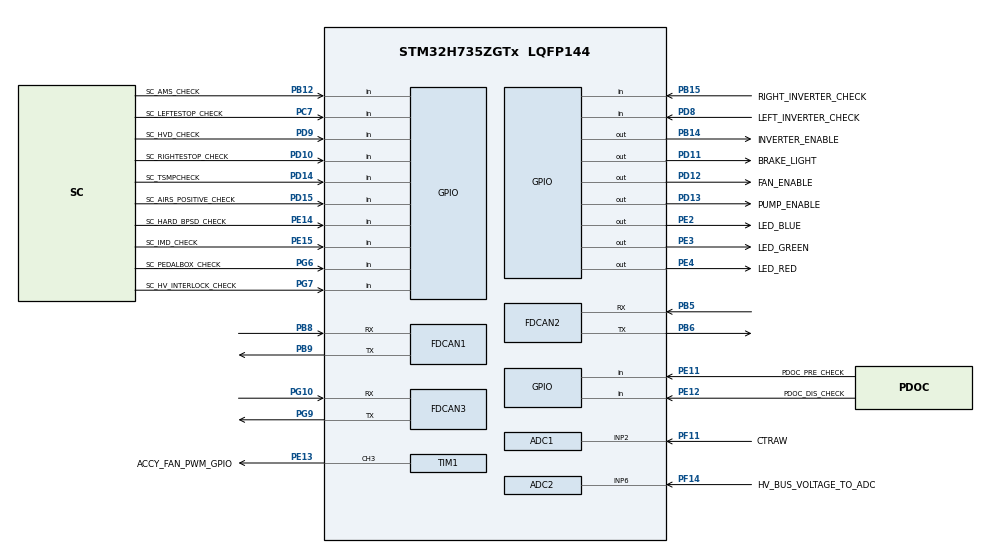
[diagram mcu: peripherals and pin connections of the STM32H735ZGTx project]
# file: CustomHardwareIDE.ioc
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ADC1.Channel-0\#ChannelRegularConversion=ADC_CHANNEL_2
ADC1.ClockPrescaler=ADC_CLOCK_ASYNC_DIV6
ADC1.NbrOfConversionFlag=1
ADC1.OffsetNumber-0\#ChannelRegularConversion=ADC_OFFSET_NONE
ADC1.OffsetSignedSaturation-0\#ChannelRegularConversion=DISABLE
ADC1.Rank-0\#ChannelRegularConversion=1
ADC1.SamplingTime-0\#ChannelRegularConversion=ADC_SAMPLETIME_1CYCLE_5
ADC1.master=1
ADC2.Channel-0\#ChannelRegularConversion=ADC_CHANNEL_6
ADC2.ClockPrescaler=ADC_CLOCK_ASYNC_DIV6
ADC2.NbrOfConversionFlag=1
ADC2.OffsetNumber-0\#ChannelRegularConversion=ADC_OFFSET_NONE
ADC2.OffsetSignedSaturation-0\#ChannelRegularConversion=DISABLE
ADC2.Rank-0\#ChannelRegularConversion=1
ADC2.SamplingTime-0\#ChannelRegularConversion=ADC_SAMPLETIME_1CYCLE_5
FDCAN1.CalculateBaudRateNominal=1062500
FDCAN1.CalculateTimeBitNominal=941
FDCAN1.CalculateTimeQuantumNominal=29.41176470588235
FDCAN1.DataPrescaler=1
FDCAN1.DataSyncJumpWidth=4
FDCAN1.DataTimeSeg1=27
FDCAN1.DataTimeSeg2=4
FDCAN1.NominalPrescaler=1
FDCAN1.NominalSyncJumpWidth=4
FDCAN1.NominalTimeSeg1=27
FDCAN1.NominalTimeSeg2=4
FDCAN1.RxFifo0ElmtSize=FDCAN_DATA_BYTES_12
FDCAN1.RxFifo0ElmtsNbr=1
FDCAN1.TxElmtSize=FDCAN_DATA_BYTES_12
FDCAN1.TxFifoQueueElmtsNbr=1
FDCAN2.CalculateBaudRateNominal=708333
FDCAN2.CalculateTimeBitNominal=1411
FDCAN2.CalculateTimeQuantumNominal=470.5882352941176
FDCAN3.CalculateBaudRateNominal=708333
FDCAN3.CalculateTimeBitNominal=1411
FDCAN3.CalculateTimeQuantumNominal=470.5882352941176
FREERTOS.Tasks01=defaultTask,24,128,StartDefaultTask,Default,NULL,Dynamic,NULL,NULL
FREERTOS.configTIMER_TASK_PRIORITY=45
FREERTOS.configUSE_NEWLIB_REENTRANT=1
Mcu.Family=STM32H7
Mcu.Name=STM32H735ZGTx
Mcu.Package=LQFP144
NVIC.FDCAN1_IT0_IRQn=true\:5\:0\:false\:false\:true\:true\:true\:true\:true
NVIC.PriorityGroup=NVIC_PRIORITYGROUP_4
NVIC.TIM2_IRQn=true\:15\:0\:false\:false\:true\:false\:false\:true\:true
NVIC.TimeBase=TIM2_IRQn
NVIC.TimeBaseIP=TIM2
PA13(JTMS/SWDIO).Mode=JTAG_5_pins
PA13(JTMS/SWDIO).Signal=DEBUG_JTMS-SWDIO
PA14(JTCK/SWCLK).Mode=JTAG_5_pins
PA14(JTCK/SWCLK).Signal=DEBUG_JTCK-SWCLK
PA15(JTDI).Mode=JTAG_5_pins
PA15(JTDI).Signal=DEBUG_JTDI
PB12.GPIO_Label=SC_AMS_CHECK
PB12.Signal=GPIO_Input
PB14.GPIO_Label=INVERTER_ENABLE
PB14.Signal=GPIO_Output
PB15.GPIO_Label=RIGHT_INVERTER_CHECK
PB15.Signal=GPIO_Input
PB3(JTDO/TRACESWO).Mode=JTAG_5_pins
PB3(JTDO/TRACESWO).Signal=DEBUG_JTDO-SWO
PB4(NJTRST).Mode=JTAG_5_pins
PB4(NJTRST).Signal=DEBUG_JTRST
PB5.Mode=FDCAN_Activate
PB5.Signal=FDCAN2_RX
PB6.Mode=FDCAN_Activate
PB6.Signal=FDCAN2_TX
PB8.Mode=FDCAN_Activate
PB8.Signal=FDCAN1_RX
PB9.Mode=FDCAN_Activate
PB9.Signal=FDCAN1_TX
PC7.GPIO_Label=SC_LEFTESTOP_CHECK
PC7.Signal=GPIO_Input
PD10.GPIO_Label=SC_RIGHTESTOP_CHECK
PD10.Signal=GPIO_Input
PD11.GPIO_Label=BRAKE_LIGHT
PD11.Signal=GPIO_Output
PD12.GPIO_Label=FAN_ENABLE
PD12.Signal=GPIO_Output
PD13.GPIO_Label=PUMP_ENABLE
PD13.Signal=GPIO_Output
PD14.GPIO_Label=SC_TSMPCHECK
PD14.Signal=GPIO_Input
PD15.GPIO_Label=SC_AIRS_POSITIVE_CHECK
PD15.Signal=GPIO_Input
PD8.GPIO_Label=LEFT_INVERTER_CHECK
PD8.Signal=GPIO_Input
PD9.GPIO_Label=SC_HVD_CHECK
PD9.Signal=GPIO_Input
PE11.GPIO_Label=PDOC_PRE_CHECK
PE11.Signal=GPIO_Input
PE12.GPIO_Label=PDOC_DIS_CHECK
PE12.Signal=GPIO_Input
PE13.GPIO_Label=ACCY_FAN_PWM_GPIO
PE13.Signal=S_TIM1_CH3
PE14.GPIO_Label=SC_HARD_BPSD_CHECK
PE14.Signal=GPIO_Input
PE15.GPIO_Label=SC_IMD_CHECK
PE15.Signal=GPIO_Input
PE2.GPIO_Label=LED_BLUE
PE2.Signal=GPIO_Output
PE3.GPIO_Label=LED_GREEN
PE3.Signal=GPIO_Output
PE4.GPIO_Label=LED_RED
PE4.GPIO_PuPd=GPIO_NOPULL
PE4.Signal=GPIO_Output
PF11.GPIO_Label=CTRAW
PF11.Mode=IN2-Single-Ended
PF11.Signal=ADC1_INP2
PF14.GPIO_Label=HV_BUS_VOLTAGE_TO_ADC
PF14.Mode=IN6-Single-Ended
PF14.Signal=ADC2_INP6
PG10.Mode=FDCAN_Activate
PG10.Signal=FDCAN3_RX
PG6.GPIO_Label=SC_PEDALBOX_CHECK
PG6.Signal=GPIO_Input
PG7.GPIO_Label=SC_HV_INTERLOCK_CHECK
PG7.Signal=GPIO_Input
PG9.Mode=FDCAN_Activate
PG9.Signal=FDCAN3_TX
PH0-OSC_IN.Mode=HSE-External-Oscillator
PH0-OSC_IN.Signal=RCC_OSC_IN
PH1-OSC_OUT.Mode=HSE-External-Oscillator
PH1-OSC_OUT.Signal=RCC_OSC_OUT
ProjectManager.HeapSize=0x200
ProjectManager.StackSize=0x400
ProjectManager.TargetToolchain=STM32CubeIDE
RCC.ADCCLockSelection=RCC_ADCCLKSOURCE_CLKP
RCC.ADCFreq_Value=64000000
RCC.APB1Freq_Value=136000000
RCC.APB2Freq_Value=136000000
RCC.APB3Freq_Value=136000000
RCC.APB4Freq_Value=136000000
RCC.CortexFreq_Value=544000000
RCC.D1PPRE=RCC_APB3_DIV2
RCC.D2PPRE1=RCC_APB1_DIV2
RCC.D2PPRE2=RCC_APB2_DIV2
RCC.D3PPRE=RCC_APB4_DIV2
RCC.DIVM1=8
RCC.DIVM2=1
RCC.DIVN1=68
RCC.DIVN2=384
RCC.DIVP1=1
RCC.DIVP2=4
RCC.DIVQ1=16
RCC.HCLKFreq_Value=272000000
RCC.HPRE=RCC_HCLK_DIV2
RCC.HSE_VALUE=16000000
RCC.SYSCLKFreq_VALUE=544000000
RCC.SYSCLKSource=RCC_SYSCLKSOURCE_PLLCLK
RCC.SupplySource=PWR_LDO_SUPPLY
RCC.USBFreq_Value=34000000
SH.S_TIM1_CH3.0=TIM1_CH3,PWM Generation3 CH3
TIM1.Channel-PWM\ Generation3\ CH3=TIM_CHANNEL_3
VP_FREERTOS_VS_CMSIS_V2.Mode=CMSIS_V2
VP_MEMORYMAP_VS_MEMORYMAP.Mode=CurAppReg
VP_SYS_VS_tim2.Mode=TIM2
VP_TIM1_VS_ClockSourceITR.Mode=TriggerSource_ITR0
VP_TIM1_VS_ControllerModeClock.Mode=Clock Mode
board=custom

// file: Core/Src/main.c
/* USER CODE BEGIN Header */
/**
  ******************************************************************************
  * @file           : main.c
  * @brief          : Main program body
  ******************************************************************************
  * @attention
  *
  * Copyright (c) 2025 STMicroelectronics.
  * All rights reserved.
  *
  * This software is licensed under terms that can be found in the LICENSE file
  * in the root directory of this software component.
  * If no LICENSE file comes with this software, it is provided AS-IS.
  *
  ******************************************************************************
  */
/* USER CODE END Header */
#include "main.h"
#include "cmsis_os.h"

FDCAN_HandleTypeDef hfdcan1;
FDCAN_HandleTypeDef hfdcan2;
FDCAN_HandleTypeDef hfdcan3;

/* Definitions for defaultTask */
osThreadId_t defaultTaskHandle;
const osThreadAttr_t defaultTask_attributes = {
  .name = "defaultTask",
  .stack_size = 128 * 4,
  .priority = (osPriority_t) osPriorityNormal,
};

void SystemClock_Config(void);
void PeriphCommonClock_Config(void);
static void MX_FDCAN1_Init(void);
static void MX_FDCAN2_Init(void);
static void MX_FDCAN3_Init(void);
static void MX_ADC1_Init(void);
static void MX_ADC2_Init(void);
static void MX_TIM1_Init(void);
void StartDefaultTask(void *argument);

int main(void)
{

  /* MCU Configuration--------------------------------------------------------*/

  /* Reset of all peripherals, Initializes the Flash interface and the Systick. */
  HAL_Init();

  /* Configure the system clock */
  SystemClock_Config();

  /* Configure the peripherals common clocks */
  PeriphCommonClock_Config();

  /* Initialize all configured peripherals */
  MX_GPIO_Init();
  MX_FDCAN1_Init();
  MX_FDCAN2_Init();
  MX_FDCAN3_Init();
  MX_ADC1_Init();
  MX_ADC2_Init();
  MX_TIM1_Init();

  /* Init scheduler */
  osKernelInitialize();

  /* Create the thread(s) */
  /* creation of defaultTask */
  defaultTaskHandle = osThreadNew(StartDefaultTask, NULL, &defaultTask_attributes);

  /* Start scheduler */
  osKernelStart();

  /* We should never get here as control is now taken by the scheduler */

  /* Infinite loop */
  while (1)
  {

  }
}

void SystemClock_Config(void)
{
  LL_FLASH_SetLatency(LL_FLASH_LATENCY_3);
  while(LL_FLASH_GetLatency()!= LL_FLASH_LATENCY_3)
  {
  }
  LL_PWR_ConfigSupply(LL_PWR_LDO_SUPPLY);
  LL_PWR_SetRegulVoltageScaling(LL_PWR_REGU_VOLTAGE_SCALE0);
  while (LL_PWR_IsActiveFlag_VOS() == 0)
  {
  }
  LL_RCC_HSI_Enable();

   /* Wait till HSI is ready */
  while(LL_RCC_HSI_IsReady() != 1)
  {

  }
  LL_RCC_HSI_SetCalibTrimming(64);
  LL_RCC_HSI_SetDivider(LL_RCC_HSI_DIV1);
  LL_RCC_PLL_SetSource(LL_RCC_PLLSOURCE_HSI);
  LL_RCC_PLL1P_Enable();
  LL_RCC_PLL1Q_Enable();
  LL_RCC_PLL1R_Enable();
  LL_RCC_PLL1_SetVCOInputRange(LL_RCC_PLLINPUTRANGE_8_16);
  LL_RCC_PLL1_SetVCOOutputRange(LL_RCC_PLLVCORANGE_WIDE);
  LL_RCC_PLL1_SetM(8);
  LL_RCC_PLL1_SetN(68);
  LL_RCC_PLL1_SetP(1);
  LL_RCC_PLL1_SetQ(16);
  LL_RCC_PLL1_SetR(2);
  LL_RCC_PLL1_Enable();

   /* Wait till PLL is ready */
  while(LL_RCC_PLL1_IsReady() != 1)
  {
  }

   /* Intermediate AHB prescaler 2 when target frequency clock is higher than 80 MHz */
   LL_RCC_SetAHBPrescaler(LL_RCC_AHB_DIV_2);

  LL_RCC_SetSysClkSource(LL_RCC_SYS_CLKSOURCE_PLL1);

   /* Wait till System clock is ready */
  while(LL_RCC_GetSysClkSource() != LL_RCC_SYS_CLKSOURCE_STATUS_PLL1)
  {

  }
  LL_RCC_SetSysPrescaler(LL_RCC_SYSCLK_DIV_1);
  LL_RCC_SetAHBPrescaler(LL_RCC_AHB_DIV_2);
  LL_RCC_SetAPB1Prescaler(LL_RCC_APB1_DIV_2);
  LL_RCC_SetAPB2Prescaler(LL_RCC_APB2_DIV_2);
  LL_RCC_SetAPB3Prescaler(LL_RCC_APB3_DIV_2);
  LL_RCC_SetAPB4Prescaler(LL_RCC_APB4_DIV_2);
  LL_SetSystemCoreClock(544000000);

   /* Update the time base */
  if (HAL_InitTick (TICK_INT_PRIORITY) != HAL_OK)
  {
    Error_Handler();
  }
}

void PeriphCommonClock_Config(void)
{
  LL_RCC_SetCLKPClockSource(LL_RCC_CLKP_CLKSOURCE_HSI);
}

static void MX_ADC1_Init(void)
{

  LL_ADC_InitTypeDef ADC_InitStruct = {0};
  LL_ADC_REG_InitTypeDef ADC_REG_InitStruct = {0};
  LL_ADC_CommonInitTypeDef ADC_CommonInitStruct = {0};

  LL_GPIO_InitTypeDef GPIO_InitStruct = {0};

  LL_RCC_SetADCClockSource(LL_RCC_ADC_CLKSOURCE_CLKP);

  /* Peripheral clock enable */
  LL_AHB1_GRP1_EnableClock(LL_AHB1_GRP1_PERIPH_ADC12);

  LL_AHB4_GRP1_EnableClock(LL_AHB4_GRP1_PERIPH_GPIOF);
  /**ADC1 GPIO Configuration
  PF11   ------> ADC1_INP2
  */
  GPIO_InitStruct.Pin = CTRAW_Pin;
  GPIO_InitStruct.Mode = LL_GPIO_MODE_ANALOG;
  GPIO_InitStruct.Pull = LL_GPIO_PULL_NO;
  LL_GPIO_Init(CTRAW_GPIO_Port, &GPIO_InitStruct);

  /** Common config
  */
  LL_ADC_SetOverSamplingScope(ADC1, LL_ADC_OVS_DISABLE);
  ADC_InitStruct.Resolution = LL_ADC_RESOLUTION_16B;
  ADC_InitStruct.LowPowerMode = LL_ADC_LP_MODE_NONE;
  LL_ADC_Init(ADC1, &ADC_InitStruct);
  ADC_REG_InitStruct.TriggerSource = LL_ADC_REG_TRIG_SOFTWARE;
  ADC_REG_InitStruct.SequencerLength = LL_ADC_REG_SEQ_SCAN_DISABLE;
  ADC_REG_InitStruct.SequencerDiscont = DISABLE;
  ADC_REG_InitStruct.ContinuousMode = LL_ADC_REG_CONV_SINGLE;
  ADC_REG_InitStruct.Overrun = LL_ADC_REG_OVR_DATA_PRESERVED;
  LL_ADC_REG_Init(ADC1, &ADC_REG_InitStruct);
  LL_ADC_REG_SetDataTransferMode(ADC1, LL_ADC_REG_DR_TRANSFER);
  ADC_CommonInitStruct.CommonClock = LL_ADC_CLOCK_ASYNC_DIV6;
  ADC_CommonInitStruct.Multimode = LL_ADC_MULTI_INDEPENDENT;
  LL_ADC_CommonInit(__LL_ADC_COMMON_INSTANCE(ADC1), &ADC_CommonInitStruct);

  /* Disable ADC deep power down (enabled by default after reset state) */
  LL_ADC_DisableDeepPowerDown(ADC1);
  /* Enable ADC internal voltage regulator */
  LL_ADC_EnableInternalRegulator(ADC1);
  /* Delay for ADC internal voltage regulator stabilization. */
  /* Compute number of CPU cycles to wait for, from delay in us. */
  /* Note: Variable divided by 2 to compensate partially */
  /* CPU processing cycles (depends on compilation optimization). */
  /* Note: If system core clock frequency is below 200kHz, wait time */
  /* is only a few CPU processing cycles. */
  __IO uint32_t wait_loop_index;
  wait_loop_index = ((LL_ADC_DELAY_INTERNAL_REGUL_STAB_US * (SystemCoreClock / (100000 * 2))) / 10);
  while(wait_loop_index != 0)
  {
    wait_loop_index--;
  }

  /** Configure Regular Channel
  */
  LL_ADC_REG_SetSequencerRanks(ADC1, LL_ADC_REG_RANK_1, LL_ADC_CHANNEL_2);
  LL_ADC_SetChannelSamplingTime(ADC1, LL_ADC_CHANNEL_2, LL_ADC_SAMPLINGTIME_1CYCLE_5);
  LL_ADC_SetChannelSingleDiff(ADC1, LL_ADC_CHANNEL_2, LL_ADC_SINGLE_ENDED);
  LL_ADC_SetChannelPreselection(ADC1, LL_ADC_CHANNEL_2);

}

static void MX_ADC2_Init(void)
{

  LL_ADC_InitTypeDef ADC_InitStruct = {0};
  LL_ADC_REG_InitTypeDef ADC_REG_InitStruct = {0};

  LL_GPIO_InitTypeDef GPIO_InitStruct = {0};

  LL_RCC_SetADCClockSource(LL_RCC_ADC_CLKSOURCE_CLKP);

  /* Peripheral clock enable */
  LL_AHB1_GRP1_EnableClock(LL_AHB1_GRP1_PERIPH_ADC12);

  LL_AHB4_GRP1_EnableClock(LL_AHB4_GRP1_PERIPH_GPIOF);
  /**ADC2 GPIO Configuration
  PF14   ------> ADC2_INP6
  */
  GPIO_InitStruct.Pin = HV_BUS_VOLTAGE_TO_ADC_Pin;
  GPIO_InitStruct.Mode = LL_GPIO_MODE_ANALOG;
  GPIO_InitStruct.Pull = LL_GPIO_PULL_NO;
  LL_GPIO_Init(HV_BUS_VOLTAGE_TO_ADC_GPIO_Port, &GPIO_InitStruct);

  /** Common config
  */
  LL_ADC_SetOverSamplingScope(ADC2, LL_ADC_OVS_DISABLE);
  ADC_InitStruct.Resolution = LL_ADC_RESOLUTION_16B;
  ADC_InitStruct.LowPowerMode = LL_ADC_LP_MODE_NONE;
  LL_ADC_Init(ADC2, &ADC_InitStruct);
  ADC_REG_InitStruct.TriggerSource = LL_ADC_REG_TRIG_SOFTWARE;
  ADC_REG_InitStruct.SequencerLength = LL_ADC_REG_SEQ_SCAN_DISABLE;
  ADC_REG_InitStruct.SequencerDiscont = DISABLE;
  ADC_REG_InitStruct.ContinuousMode = LL_ADC_REG_CONV_SINGLE;
  ADC_REG_InitStruct.Overrun = LL_ADC_REG_OVR_DATA_PRESERVED;
  LL_ADC_REG_Init(ADC2, &ADC_REG_InitStruct);
  LL_ADC_REG_SetDataTransferMode(ADC2, LL_ADC_REG_DR_TRANSFER);

  /* Disable ADC deep power down (enabled by default after reset state) */
  LL_ADC_DisableDeepPowerDown(ADC2);
  /* Enable ADC internal voltage regulator */
  LL_ADC_EnableInternalRegulator(ADC2);
  /* Delay for ADC internal voltage regulator stabilization. */
  /* Compute number of CPU cycles to wait for, from delay in us. */
  /* Note: Variable divided by 2 to compensate partially */
  /* CPU processing cycles (depends on compilation optimization). */
  /* Note: If system core clock frequency is below 200kHz, wait time */
  /* is only a few CPU processing cycles. */
  __IO uint32_t wait_loop_index;
  wait_loop_index = ((LL_ADC_DELAY_INTERNAL_REGUL_STAB_US * (SystemCoreClock / (100000 * 2))) / 10);
  while(wait_loop_index != 0)
  {
    wait_loop_index--;
  }

  /** Configure Regular Channel
  */
  LL_ADC_REG_SetSequencerRanks(ADC2, LL_ADC_REG_RANK_1, LL_ADC_CHANNEL_6);
  LL_ADC_SetChannelSamplingTime(ADC2, LL_ADC_CHANNEL_6, LL_ADC_SAMPLINGTIME_1CYCLE_5);
  LL_ADC_SetChannelSingleDiff(ADC2, LL_ADC_CHANNEL_6, LL_ADC_SINGLE_ENDED);
  LL_ADC_SetChannelPreselection(ADC2, LL_ADC_CHANNEL_6);

}

static void MX_FDCAN1_Init(void)
{

  hfdcan1.Instance = FDCAN1;
  hfdcan1.Init.FrameFormat = FDCAN_FRAME_CLASSIC;
  hfdcan1.Init.Mode = FDCAN_MODE_NORMAL;
  hfdcan1.Init.AutoRetransmission = DISABLE;
  hfdcan1.Init.TransmitPause = DISABLE;
  hfdcan1.Init.ProtocolException = DISABLE;
  hfdcan1.Init.NominalPrescaler = 1;
  hfdcan1.Init.NominalSyncJumpWidth = 4;
  hfdcan1.Init.NominalTimeSeg1 = 27;
  hfdcan1.Init.NominalTimeSeg2 = 4;
  hfdcan1.Init.DataPrescaler = 1;
  hfdcan1.Init.DataSyncJumpWidth = 4;
  hfdcan1.Init.DataTimeSeg1 = 27;
  hfdcan1.Init.DataTimeSeg2 = 4;
  hfdcan1.Init.MessageRAMOffset = 0;
  hfdcan1.Init.StdFiltersNbr = 0;
  hfdcan1.Init.ExtFiltersNbr = 0;
  hfdcan1.Init.RxFifo0ElmtsNbr = 1;
  hfdcan1.Init.RxFifo0ElmtSize = FDCAN_DATA_BYTES_12;
  hfdcan1.Init.RxFifo1ElmtsNbr = 0;
  hfdcan1.Init.RxFifo1ElmtSize = FDCAN_DATA_BYTES_8;
  hfdcan1.Init.RxBuffersNbr = 0;
  hfdcan1.Init.RxBufferSize = FDCAN_DATA_BYTES_8;
  hfdcan1.Init.TxEventsNbr = 0;
  hfdcan1.Init.TxBuffersNbr = 0;
  hfdcan1.Init.TxFifoQueueElmtsNbr = 1;
  hfdcan1.Init.TxFifoQueueMode = FDCAN_TX_FIFO_OPERATION;
  hfdcan1.Init.TxElmtSize = FDCAN_DATA_BYTES_12;
  if (HAL_FDCAN_Init(&hfdcan1) != HAL_OK)
  {
    Error_Handler();
  }

}

static void MX_FDCAN2_Init(void)
{

  hfdcan2.Instance = FDCAN2;
  hfdcan2.Init.FrameFormat = FDCAN_FRAME_CLASSIC;
  hfdcan2.Init.Mode = FDCAN_MODE_NORMAL;
  hfdcan2.Init.AutoRetransmission = DISABLE;
  hfdcan2.Init.TransmitPause = DISABLE;
  hfdcan2.Init.ProtocolException = DISABLE;
  hfdcan2.Init.NominalPrescaler = 16;
  hfdcan2.Init.NominalSyncJumpWidth = 1;
  hfdcan2.Init.NominalTimeSeg1 = 1;
  hfdcan2.Init.NominalTimeSeg2 = 1;
  hfdcan2.Init.DataPrescaler = 1;
  hfdcan2.Init.DataSyncJumpWidth = 1;
  hfdcan2.Init.DataTimeSeg1 = 1;
  hfdcan2.Init.DataTimeSeg2 = 1;
  hfdcan2.Init.MessageRAMOffset = 0;
  hfdcan2.Init.StdFiltersNbr = 0;
  hfdcan2.Init.ExtFiltersNbr = 0;
  hfdcan2.Init.RxFifo0ElmtsNbr = 0;
  hfdcan2.Init.RxFifo0ElmtSize = FDCAN_DATA_BYTES_8;
  hfdcan2.Init.RxFifo1ElmtsNbr = 0;
  hfdcan2.Init.RxFifo1ElmtSize = FDCAN_DATA_BYTES_8;
  hfdcan2.Init.RxBuffersNbr = 0;
  hfdcan2.Init.RxBufferSize = FDCAN_DATA_BYTES_8;
  hfdcan2.Init.TxEventsNbr = 0;
  hfdcan2.Init.TxBuffersNbr = 0;
  hfdcan2.Init.TxFifoQueueElmtsNbr = 0;
  hfdcan2.Init.TxFifoQueueMode = FDCAN_TX_FIFO_OPERATION;
  hfdcan2.Init.TxElmtSize = FDCAN_DATA_BYTES_8;
  if (HAL_FDCAN_Init(&hfdcan2) != HAL_OK)
  {
    Error_Handler();
  }

}

static void MX_FDCAN3_Init(void)
{

  hfdcan3.Instance = FDCAN3;
  hfdcan3.Init.FrameFormat = FDCAN_FRAME_CLASSIC;
  hfdcan3.Init.Mode = FDCAN_MODE_NORMAL;
  hfdcan3.Init.AutoRetransmission = DISABLE;
  hfdcan3.Init.TransmitPause = DISABLE;
  hfdcan3.Init.ProtocolException = DISABLE;
  hfdcan3.Init.NominalPrescaler = 16;
  hfdcan3.Init.NominalSyncJumpWidth = 1;
  hfdcan3.Init.NominalTimeSeg1 = 1;
  hfdcan3.Init.NominalTimeSeg2 = 1;
  hfdcan3.Init.DataPrescaler = 1;
  hfdcan3.Init.DataSyncJumpWidth = 1;
  hfdcan3.Init.DataTimeSeg1 = 1;
  hfdcan3.Init.DataTimeSeg2 = 1;
  hfdcan3.Init.MessageRAMOffset = 0;
  hfdcan3.Init.StdFiltersNbr = 0;
  hfdcan3.Init.ExtFiltersNbr = 0;
  hfdcan3.Init.RxFifo0ElmtsNbr = 0;
  hfdcan3.Init.RxFifo0ElmtSize = FDCAN_DATA_BYTES_8;
  hfdcan3.Init.RxFifo1ElmtsNbr = 0;
  hfdcan3.Init.RxFifo1ElmtSize = FDCAN_DATA_BYTES_8;
  hfdcan3.Init.RxBuffersNbr = 0;
  hfdcan3.Init.RxBufferSize = FDCAN_DATA_BYTES_8;
  hfdcan3.Init.TxEventsNbr = 0;
  hfdcan3.Init.TxBuffersNbr = 0;
  hfdcan3.Init.TxFifoQueueElmtsNbr = 0;
  hfdcan3.Init.TxFifoQueueMode = FDCAN_TX_FIFO_OPERATION;
  hfdcan3.Init.TxElmtSize = FDCAN_DATA_BYTES_8;
  if (HAL_FDCAN_Init(&hfdcan3) != HAL_OK)
  {
    Error_Handler();
  }

}

static void MX_TIM1_Init(void)
{

  LL_TIM_InitTypeDef TIM_InitStruct = {0};
  LL_TIM_OC_InitTypeDef TIM_OC_InitStruct = {0};
  LL_TIM_BDTR_InitTypeDef TIM_BDTRInitStruct = {0};

  LL_GPIO_InitTypeDef GPIO_InitStruct = {0};

  /* Peripheral clock enable */
  LL_APB2_GRP1_EnableClock(LL_APB2_GRP1_PERIPH_TIM1);

  TIM_InitStruct.Prescaler = 0;
  TIM_InitStruct.CounterMode = LL_TIM_COUNTERMODE_UP;
  TIM_InitStruct.Autoreload = 65535;
  TIM_InitStruct.ClockDivision = LL_TIM_CLOCKDIVISION_DIV1;
  TIM_InitStruct.RepetitionCounter = 0;
  LL_TIM_Init(TIM1, &TIM_InitStruct);
  LL_TIM_DisableARRPreload(TIM1);
  LL_TIM_OC_EnablePreload(TIM1, LL_TIM_CHANNEL_CH3);
  TIM_OC_InitStruct.OCMode = LL_TIM_OCMODE_PWM1;
  TIM_OC_InitStruct.OCState = LL_TIM_OCSTATE_DISABLE;
  TIM_OC_InitStruct.OCNState = LL_TIM_OCSTATE_DISABLE;
  TIM_OC_InitStruct.CompareValue = 0;
  TIM_OC_InitStruct.OCPolarity = LL_TIM_OCPOLARITY_HIGH;
  TIM_OC_InitStruct.OCNPolarity = LL_TIM_OCPOLARITY_HIGH;
  TIM_OC_InitStruct.OCIdleState = LL_TIM_OCIDLESTATE_LOW;
  TIM_OC_InitStruct.OCNIdleState = LL_TIM_OCIDLESTATE_LOW;
  LL_TIM_OC_Init(TIM1, LL_TIM_CHANNEL_CH3, &TIM_OC_InitStruct);
  LL_TIM_OC_DisableFast(TIM1, LL_TIM_CHANNEL_CH3);
  LL_TIM_SetTriggerInput(TIM1, LL_TIM_TS_ITR0);
  LL_TIM_SetClockSource(TIM1, LL_TIM_CLOCKSOURCE_EXT_MODE1);
  LL_TIM_DisableIT_TRIG(TIM1);
  LL_TIM_DisableDMAReq_TRIG(TIM1);
  LL_TIM_SetTriggerOutput(TIM1, LL_TIM_TRGO_RESET);
  LL_TIM_SetTriggerOutput2(TIM1, LL_TIM_TRGO2_RESET);
  LL_TIM_DisableMasterSlaveMode(TIM1);
  TIM_BDTRInitStruct.OSSRState = LL_TIM_OSSR_DISABLE;
  TIM_BDTRInitStruct.OSSIState = LL_TIM_OSSI_DISABLE;
  TIM_BDTRInitStruct.LockLevel = LL_TIM_LOCKLEVEL_OFF;
  TIM_BDTRInitStruct.DeadTime = 0;
  TIM_BDTRInitStruct.BreakState = LL_TIM_BREAK_DISABLE;
  TIM_BDTRInitStruct.BreakPolarity = LL_TIM_BREAK_POLARITY_HIGH;
  TIM_BDTRInitStruct.BreakFilter = LL_TIM_BREAK_FILTER_FDIV1;
  TIM_BDTRInitStruct.Break2State = LL_TIM_BREAK2_DISABLE;
  TIM_BDTRInitStruct.Break2Polarity = LL_TIM_BREAK2_POLARITY_HIGH;
  TIM_BDTRInitStruct.Break2Filter = LL_TIM_BREAK2_FILTER_FDIV1;
  TIM_BDTRInitStruct.AutomaticOutput = LL_TIM_AUTOMATICOUTPUT_DISABLE;
  LL_TIM_BDTR_Init(TIM1, &TIM_BDTRInitStruct);
  LL_AHB4_GRP1_EnableClock(LL_AHB4_GRP1_PERIPH_GPIOE);
  /**TIM1 GPIO Configuration
  PE13   ------> TIM1_CH3
  */
  GPIO_InitStruct.Pin = ACCY_FAN_PWM_GPIO_Pin;
  GPIO_InitStruct.Mode = LL_GPIO_MODE_ALTERNATE;
  GPIO_InitStruct.Speed = LL_GPIO_SPEED_FREQ_LOW;
  GPIO_InitStruct.OutputType = LL_GPIO_OUTPUT_PUSHPULL;
  GPIO_InitStruct.Pull = LL_GPIO_PULL_NO;
  GPIO_InitStruct.Alternate = LL_GPIO_AF_1;
  LL_GPIO_Init(ACCY_FAN_PWM_GPIO_GPIO_Port, &GPIO_InitStruct);

}

void MX_GPIO_Init(void)
{
  LL_GPIO_InitTypeDef GPIO_InitStruct = {0};

  /* GPIO Ports Clock Enable */
  LL_AHB4_GRP1_EnableClock(LL_AHB4_GRP1_PERIPH_GPIOE);
  LL_AHB4_GRP1_EnableClock(LL_AHB4_GRP1_PERIPH_GPIOH);
  LL_AHB4_GRP1_EnableClock(LL_AHB4_GRP1_PERIPH_GPIOF);
  LL_AHB4_GRP1_EnableClock(LL_AHB4_GRP1_PERIPH_GPIOB);
  LL_AHB4_GRP1_EnableClock(LL_AHB4_GRP1_PERIPH_GPIOD);
  LL_AHB4_GRP1_EnableClock(LL_AHB4_GRP1_PERIPH_GPIOG);
  LL_AHB4_GRP1_EnableClock(LL_AHB4_GRP1_PERIPH_GPIOC);
  LL_AHB4_GRP1_EnableClock(LL_AHB4_GRP1_PERIPH_GPIOA);

  /**/
  LL_GPIO_ResetOutputPin(GPIOE, LED_BLUE_Pin|LED_GREEN_Pin|LED_RED_Pin);

  /**/
  LL_GPIO_ResetOutputPin(INVERTER_ENABLE_GPIO_Port, INVERTER_ENABLE_Pin);

  /**/
  LL_GPIO_ResetOutputPin(GPIOD, BRAKE_LIGHT_Pin|FAN_ENABLE_Pin|PUMP_ENABLE_Pin);

  /**/
  GPIO_InitStruct.Pin = LED_BLUE_Pin|LED_GREEN_Pin|LED_RED_Pin;
  GPIO_InitStruct.Mode = LL_GPIO_MODE_OUTPUT;
  GPIO_InitStruct.Speed = LL_GPIO_SPEED_FREQ_LOW;
  GPIO_InitStruct.OutputType = LL_GPIO_OUTPUT_PUSHPULL;
  GPIO_InitStruct.Pull = LL_GPIO_PULL_NO;
  LL_GPIO_Init(GPIOE, &GPIO_InitStruct);

  /**/
  GPIO_InitStruct.Pin = PDOC_PRE_CHECK_Pin|PDOC_DIS_CHECK_Pin|SC_HARD_BPSD_CHECK_Pin|SC_IMD_CHECK_Pin;
  GPIO_InitStruct.Mode = LL_GPIO_MODE_INPUT;
  GPIO_InitStruct.Pull = LL_GPIO_PULL_NO;
  LL_GPIO_Init(GPIOE, &GPIO_InitStruct);

  /**/
  GPIO_InitStruct.Pin = SC_AMS_CHECK_Pin|RIGHT_INVERTER_CHECK_Pin;
  GPIO_InitStruct.Mode = LL_GPIO_MODE_INPUT;
  GPIO_InitStruct.Pull = LL_GPIO_PULL_NO;
  LL_GPIO_Init(GPIOB, &GPIO_InitStruct);

  /**/
  GPIO_InitStruct.Pin = INVERTER_ENABLE_Pin;
  GPIO_InitStruct.Mode = LL_GPIO_MODE_OUTPUT;
  GPIO_InitStruct.Speed = LL_GPIO_SPEED_FREQ_LOW;
  GPIO_InitStruct.OutputType = LL_GPIO_OUTPUT_PUSHPULL;
  GPIO_InitStruct.Pull = LL_GPIO_PULL_NO;
  LL_GPIO_Init(INVERTER_ENABLE_GPIO_Port, &GPIO_InitStruct);

  /**/
  GPIO_InitStruct.Pin = LEFT_INVERTER_CHECK_Pin|SC_HVD_CHECK_Pin|SC_RIGHTESTOP_CHECK_Pin|SC_TSMPCHECK_Pin
                          |SC_AIRS_POSITIVE_CHECK_Pin;
  GPIO_InitStruct.Mode = LL_GPIO_MODE_INPUT;
  GPIO_InitStruct.Pull = LL_GPIO_PULL_NO;
  LL_GPIO_Init(GPIOD, &GPIO_InitStruct);

  /**/
  GPIO_InitStruct.Pin = BRAKE_LIGHT_Pin|FAN_ENABLE_Pin|PUMP_ENABLE_Pin;
  GPIO_InitStruct.Mode = LL_GPIO_MODE_OUTPUT;
  GPIO_InitStruct.Speed = LL_GPIO_SPEED_FREQ_LOW;
  GPIO_InitStruct.OutputType = LL_GPIO_OUTPUT_PUSHPULL;
  GPIO_InitStruct.Pull = LL_GPIO_PULL_NO;
  LL_GPIO_Init(GPIOD, &GPIO_InitStruct);

  /**/
  GPIO_InitStruct.Pin = SC_PEDALBOX_CHECK_Pin|SC_HV_INTERLOCK_CHECK_Pin;
  GPIO_InitStruct.Mode = LL_GPIO_MODE_INPUT;
  GPIO_InitStruct.Pull = LL_GPIO_PULL_NO;
  LL_GPIO_Init(GPIOG, &GPIO_InitStruct);

  /**/
  GPIO_InitStruct.Pin = SC_LEFTESTOP_CHECK_Pin;
  GPIO_InitStruct.Mode = LL_GPIO_MODE_INPUT;
  GPIO_InitStruct.Pull = LL_GPIO_PULL_NO;
  LL_GPIO_Init(SC_LEFTESTOP_CHECK_GPIO_Port, &GPIO_InitStruct);

}

void StartDefaultTask(void *argument)
{
  /* USER CODE BEGIN 5 */
  /* Infinite loop */
  for(;;)
  {
    /* Toggle the red LED and wait 500 ms */
    LL_GPIO_TogglePin(LED_RED_GPIO_Port, LED_RED_Pin);
    osDelay(1000);
  }
  /* USER CODE END 5 */
}

void HAL_TIM_PeriodElapsedCallback(TIM_HandleTypeDef *htim)
{
  if (htim->Instance == TIM2)
  {
    HAL_IncTick();
  }
}

void Error_Handler(void)
{
  __disable_irq();
  while (1)
  {
  }
}
